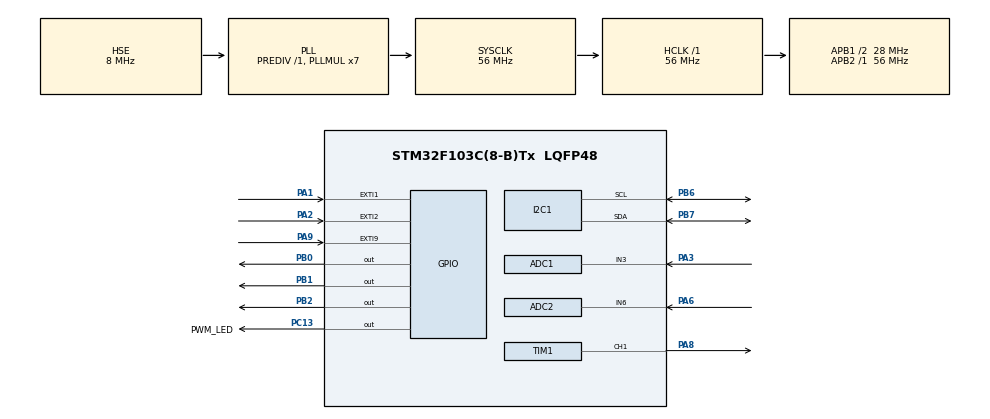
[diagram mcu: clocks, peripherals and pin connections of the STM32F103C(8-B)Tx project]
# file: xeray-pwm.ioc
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ADC1.Channel-0\#ChannelRegularConversion=ADC_CHANNEL_3
ADC1.NbrOfConversionFlag=1
ADC1.Rank-0\#ChannelRegularConversion=1
ADC1.SamplingTime-0\#ChannelRegularConversion=ADC_SAMPLETIME_1CYCLE_5
ADC1.master=1
ADC2.Channel-0\#ChannelRegularConversion=ADC_CHANNEL_6
ADC2.NbrOfConversionFlag=1
ADC2.Rank-0\#ChannelRegularConversion=1
ADC2.SamplingTime-0\#ChannelRegularConversion=ADC_SAMPLETIME_1CYCLE_5
I2C1.OwnAddress1=96
Mcu.Family=STM32F1
Mcu.Name=STM32F103C(8-B)Tx
Mcu.Package=LQFP48
NVIC.I2C1_ER_IRQn=true\:4\:0\:false\:false\:true\:true\:true\:true
NVIC.I2C1_EV_IRQn=true\:4\:0\:false\:false\:true\:true\:true\:true
NVIC.PriorityGroup=NVIC_PRIORITYGROUP_4
PA1.Signal=GPXTI1
PA13.Mode=Serial_Wire
PA13.Signal=SYS_JTMS-SWDIO
PA14.Mode=Serial_Wire
PA14.Signal=SYS_JTCK-SWCLK
PA2.Signal=GPXTI2
PA3.Signal=ADCx_IN3
PA6.Signal=ADCx_IN6
PA8.Signal=S_TIM1_CH1
PA9.Signal=GPXTI9
PB0.Signal=GPIO_Output
PB1.Signal=GPIO_Output
PB2.Signal=GPIO_Output
PB6.Mode=I2C
PB6.Signal=I2C1_SCL
PB7.Mode=I2C
PB7.Signal=I2C1_SDA
PC13-TAMPER-RTC.GPIO_Label=PWM_LED
PC13-TAMPER-RTC.Signal=GPIO_Output
PD0-OSC_IN.Mode=HSE-External-Oscillator
PD0-OSC_IN.Signal=RCC_OSC_IN
PD1-OSC_OUT.Mode=HSE-External-Oscillator
PD1-OSC_OUT.Signal=RCC_OSC_OUT
ProjectManager.HeapSize=0x200
ProjectManager.StackSize=0x400
ProjectManager.TargetToolchain=STM32CubeIDE
RCC.ADCPresc=RCC_ADCPCLK2_DIV4
RCC.AHBFreq_Value=56000000
RCC.APB1CLKDivider=RCC_HCLK_DIV2
RCC.APB1Freq_Value=28000000
RCC.APB1TimFreq_Value=56000000
RCC.APB2Freq_Value=56000000
RCC.APB2TimFreq_Value=56000000
RCC.HCLKFreq_Value=56000000
RCC.PLLMUL=RCC_PLL_MUL7
RCC.PLLSourceVirtual=RCC_PLLSOURCE_HSE
RCC.SYSCLKFreq_VALUE=56000000
RCC.SYSCLKSource=RCC_SYSCLKSOURCE_PLLCLK
RCC.USBFreq_Value=56000000
SH.ADCx_IN3.0=ADC1_IN3,IN3
SH.ADCx_IN6.0=ADC2_IN6,IN6
SH.S_TIM1_CH1.0=TIM1_CH1,PWM Generation1 CH1
TIM1.Channel-PWM\ Generation1\ CH1=TIM_CHANNEL_1
board=custom

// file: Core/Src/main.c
/* USER CODE BEGIN Header */
/**
  ******************************************************************************
  * @file           : main.c
  * @brief          : Main program body
  ******************************************************************************
  * @attention
  *
  * Copyright (c) 2026 STMicroelectronics.
  * All rights reserved.
  *
  * This software is licensed under terms that can be found in the LICENSE file
  * in the root directory of this software component.
  * If no LICENSE file comes with this software, it is provided AS-IS.
  *
  ******************************************************************************
  */
/* USER CODE END Header */
#include "main.h"

/* USER CODE BEGIN Includes */
#include "led_link.h"
/* USER CODE END Includes */

ADC_HandleTypeDef hadc1;
ADC_HandleTypeDef hadc2;

I2C_HandleTypeDef hi2c1;

TIM_HandleTypeDef htim1;

void SystemClock_Config(void);
static void MX_GPIO_Init(void);
static void MX_ADC1_Init(void);
static void MX_ADC2_Init(void);
static void MX_I2C1_Init(void);
static void MX_TIM1_Init(void);

int main(void)
{

  /* MCU Configuration--------------------------------------------------------*/

  /* Reset of all peripherals, Initializes the Flash interface and the Systick. */
  HAL_Init();

  /* Configure the system clock */
  SystemClock_Config();

  /* Initialize all configured peripherals */
  MX_GPIO_Init();
  MX_ADC1_Init();
  MX_ADC2_Init();
  MX_I2C1_Init();
  MX_TIM1_Init();
  /* USER CODE BEGIN 2 */
  LED_Link_Init();
  /* USER CODE END 2 */

  /* Infinite loop */
  while (1)
  {

    /* USER CODE BEGIN 3 */
    LED_Link_Poll();
    __WFI(); /* Wake on SysTick for the next 1 ms service interval. */
  }
  /* USER CODE END 3 */
}

void SystemClock_Config(void)
{
  RCC_OscInitTypeDef RCC_OscInitStruct = {0};
  RCC_ClkInitTypeDef RCC_ClkInitStruct = {0};
  RCC_PeriphCLKInitTypeDef PeriphClkInit = {0};

  /** Initializes the RCC Oscillators according to the specified parameters
  * in the RCC_OscInitTypeDef structure.
  */
  RCC_OscInitStruct.OscillatorType = RCC_OSCILLATORTYPE_HSE;
  RCC_OscInitStruct.HSEState = RCC_HSE_ON;
  RCC_OscInitStruct.HSEPredivValue = RCC_HSE_PREDIV_DIV1;
  RCC_OscInitStruct.HSIState = RCC_HSI_ON;
  RCC_OscInitStruct.PLL.PLLState = RCC_PLL_ON;
  RCC_OscInitStruct.PLL.PLLSource = RCC_PLLSOURCE_HSE;
  RCC_OscInitStruct.PLL.PLLMUL = RCC_PLL_MUL7;
  if (HAL_RCC_OscConfig(&RCC_OscInitStruct) != HAL_OK)
  {
    Error_Handler();
  }

  /** Initializes the CPU, AHB and APB buses clocks
  */
  RCC_ClkInitStruct.ClockType = RCC_CLOCKTYPE_HCLK|RCC_CLOCKTYPE_SYSCLK
                              |RCC_CLOCKTYPE_PCLK1|RCC_CLOCKTYPE_PCLK2;
  RCC_ClkInitStruct.SYSCLKSource = RCC_SYSCLKSOURCE_PLLCLK;
  RCC_ClkInitStruct.AHBCLKDivider = RCC_SYSCLK_DIV1;
  RCC_ClkInitStruct.APB1CLKDivider = RCC_HCLK_DIV2;
  RCC_ClkInitStruct.APB2CLKDivider = RCC_HCLK_DIV1;

  if (HAL_RCC_ClockConfig(&RCC_ClkInitStruct, FLASH_LATENCY_2) != HAL_OK)
  {
    Error_Handler();
  }
  PeriphClkInit.PeriphClockSelection = RCC_PERIPHCLK_ADC;
  PeriphClkInit.AdcClockSelection = RCC_ADCPCLK2_DIV4;
  if (HAL_RCCEx_PeriphCLKConfig(&PeriphClkInit) != HAL_OK)
  {
    Error_Handler();
  }
}

static void MX_ADC1_Init(void)
{

  ADC_ChannelConfTypeDef sConfig = {0};

  /** Common config
  */
  hadc1.Instance = ADC1;
  hadc1.Init.ScanConvMode = ADC_SCAN_DISABLE;
  hadc1.Init.ContinuousConvMode = DISABLE;
  hadc1.Init.DiscontinuousConvMode = DISABLE;
  hadc1.Init.ExternalTrigConv = ADC_SOFTWARE_START;
  hadc1.Init.DataAlign = ADC_DATAALIGN_RIGHT;
  hadc1.Init.NbrOfConversion = 1;
  if (HAL_ADC_Init(&hadc1) != HAL_OK)
  {
    Error_Handler();
  }

  /** Configure Regular Channel
  */
  sConfig.Channel = ADC_CHANNEL_3;
  sConfig.Rank = ADC_REGULAR_RANK_1;
  sConfig.SamplingTime = ADC_SAMPLETIME_1CYCLE_5;
  if (HAL_ADC_ConfigChannel(&hadc1, &sConfig) != HAL_OK)
  {
    Error_Handler();
  }

}

static void MX_ADC2_Init(void)
{

  ADC_ChannelConfTypeDef sConfig = {0};

  /** Common config
  */
  hadc2.Instance = ADC2;
  hadc2.Init.ScanConvMode = ADC_SCAN_DISABLE;
  hadc2.Init.ContinuousConvMode = DISABLE;
  hadc2.Init.DiscontinuousConvMode = DISABLE;
  hadc2.Init.ExternalTrigConv = ADC_SOFTWARE_START;
  hadc2.Init.DataAlign = ADC_DATAALIGN_RIGHT;
  hadc2.Init.NbrOfConversion = 1;
  if (HAL_ADC_Init(&hadc2) != HAL_OK)
  {
    Error_Handler();
  }

  /** Configure Regular Channel
  */
  sConfig.Channel = ADC_CHANNEL_6;
  sConfig.Rank = ADC_REGULAR_RANK_1;
  sConfig.SamplingTime = ADC_SAMPLETIME_1CYCLE_5;
  if (HAL_ADC_ConfigChannel(&hadc2, &sConfig) != HAL_OK)
  {
    Error_Handler();
  }

}

static void MX_I2C1_Init(void)
{

  hi2c1.Instance = I2C1;
  hi2c1.Init.ClockSpeed = 100000;
  hi2c1.Init.DutyCycle = I2C_DUTYCYCLE_2;
  hi2c1.Init.OwnAddress1 = 0x30U << 1;
  hi2c1.Init.AddressingMode = I2C_ADDRESSINGMODE_7BIT;
  hi2c1.Init.DualAddressMode = I2C_DUALADDRESS_DISABLE;
  hi2c1.Init.OwnAddress2 = 0;
  hi2c1.Init.GeneralCallMode = I2C_GENERALCALL_DISABLE;
  hi2c1.Init.NoStretchMode = I2C_NOSTRETCH_DISABLE;
  if (HAL_I2C_Init(&hi2c1) != HAL_OK)
  {
    Error_Handler();
  }

}

static void MX_TIM1_Init(void)
{

  TIM_MasterConfigTypeDef sMasterConfig = {0};
  TIM_OC_InitTypeDef sConfigOC = {0};
  TIM_BreakDeadTimeConfigTypeDef sBreakDeadTimeConfig = {0};

  htim1.Instance = TIM1;
  htim1.Init.Prescaler = 0;
  htim1.Init.CounterMode = TIM_COUNTERMODE_UP;
  htim1.Init.Period = 65535;
  htim1.Init.ClockDivision = TIM_CLOCKDIVISION_DIV1;
  htim1.Init.RepetitionCounter = 0;
  htim1.Init.AutoReloadPreload = TIM_AUTORELOAD_PRELOAD_DISABLE;
  if (HAL_TIM_PWM_Init(&htim1) != HAL_OK)
  {
    Error_Handler();
  }
  sMasterConfig.MasterOutputTrigger = TIM_TRGO_RESET;
  sMasterConfig.MasterSlaveMode = TIM_MASTERSLAVEMODE_DISABLE;
  if (HAL_TIMEx_MasterConfigSynchronization(&htim1, &sMasterConfig) != HAL_OK)
  {
    Error_Handler();
  }
  sConfigOC.OCMode = TIM_OCMODE_PWM1;
  sConfigOC.Pulse = 0;
  sConfigOC.OCPolarity = TIM_OCPOLARITY_HIGH;
  sConfigOC.OCNPolarity = TIM_OCNPOLARITY_HIGH;
  sConfigOC.OCFastMode = TIM_OCFAST_DISABLE;
  sConfigOC.OCIdleState = TIM_OCIDLESTATE_RESET;
  sConfigOC.OCNIdleState = TIM_OCNIDLESTATE_RESET;
  if (HAL_TIM_PWM_ConfigChannel(&htim1, &sConfigOC, TIM_CHANNEL_1) != HAL_OK)
  {
    Error_Handler();
  }
  sBreakDeadTimeConfig.OffStateRunMode = TIM_OSSR_DISABLE;
  sBreakDeadTimeConfig.OffStateIDLEMode = TIM_OSSI_DISABLE;
  sBreakDeadTimeConfig.LockLevel = TIM_LOCKLEVEL_OFF;
  sBreakDeadTimeConfig.DeadTime = 0;
  sBreakDeadTimeConfig.BreakState = TIM_BREAK_DISABLE;
  sBreakDeadTimeConfig.BreakPolarity = TIM_BREAKPOLARITY_HIGH;
  sBreakDeadTimeConfig.AutomaticOutput = TIM_AUTOMATICOUTPUT_DISABLE;
  if (HAL_TIMEx_ConfigBreakDeadTime(&htim1, &sBreakDeadTimeConfig) != HAL_OK)
  {
    Error_Handler();
  }
  HAL_TIM_MspPostInit(&htim1);

}

static void MX_GPIO_Init(void)
{
  GPIO_InitTypeDef GPIO_InitStruct = {0};

  /* GPIO Ports Clock Enable */
  __HAL_RCC_GPIOC_CLK_ENABLE();
  __HAL_RCC_GPIOD_CLK_ENABLE();
  __HAL_RCC_GPIOA_CLK_ENABLE();
  __HAL_RCC_GPIOB_CLK_ENABLE();

  /*Configure GPIO pin Output Level */
  HAL_GPIO_WritePin(GPIOC, GPIO_PIN_13, GPIO_PIN_RESET);

  /*Configure GPIO pin Output Level */
  HAL_GPIO_WritePin(GPIOB, GPIO_PIN_0|GPIO_PIN_1|GPIO_PIN_2, GPIO_PIN_RESET);

  /*Configure GPIO pin : PC13 */
  GPIO_InitStruct.Pin = GPIO_PIN_13;
  GPIO_InitStruct.Mode = GPIO_MODE_OUTPUT_PP;
  GPIO_InitStruct.Pull = GPIO_NOPULL;
  GPIO_InitStruct.Speed = GPIO_SPEED_FREQ_LOW;
  HAL_GPIO_Init(GPIOC, &GPIO_InitStruct);

  /*Configure GPIO pins : PA1 PA2 PA9 */
  GPIO_InitStruct.Pin = GPIO_PIN_1|GPIO_PIN_2|GPIO_PIN_9;
  GPIO_InitStruct.Mode = GPIO_MODE_IT_RISING;
  GPIO_InitStruct.Pull = GPIO_NOPULL;
  HAL_GPIO_Init(GPIOA, &GPIO_InitStruct);

  /*Configure GPIO pins : PB0 PB1 PB2 */
  GPIO_InitStruct.Pin = GPIO_PIN_0|GPIO_PIN_1|GPIO_PIN_2;
  GPIO_InitStruct.Mode = GPIO_MODE_OUTPUT_PP;
  GPIO_InitStruct.Pull = GPIO_NOPULL;
  GPIO_InitStruct.Speed = GPIO_SPEED_FREQ_LOW;
  HAL_GPIO_Init(GPIOB, &GPIO_InitStruct);

}

void Error_Handler(void)
{
  __disable_irq();
  while (1)
  {
  }
}
